# DEMO1 register map
A demo chip & its peripherals
CPU: CM4, FPU
Registers are 32-bit, access not given, no defined reset value unless marked. A register's access mark holds for its fields unless they carry their own. Offsets are from the block's base; lines under a group give offsets from that group; [hi:lo] are bit positions; {n}, {i} and the like mark numbered series; 'fields as' and 'values as' point back to an identical list; <NAME> marks a mode.

## Memory map
0x40000000 TIMER — A 16-bit timer
0x40004000 UART0 — Serial port
0x40020000 GPIOA — General-purpose I/O
0x40020400 GPIOB

## Interrupts
5 UART0
28 TIMER — Timer update

## GPIOA — General-purpose I/O
Base 0x40020000
Same registers: GPIOB 0x40020400
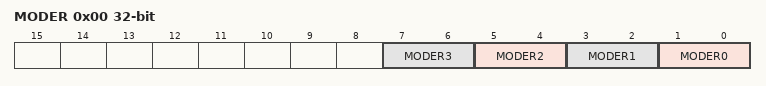
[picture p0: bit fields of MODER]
0x00 MODER — Mode register, spread over lines
  [2n+1:2n] MODER{n} (n=0..3) — Pin mode
0x14 ODR — Output data
  [1] OD1
  [0] OD0
  [0] OUT_ALIAS — Same bit as OD0
0x1C LCKR — Lock register, without fields

## TIMER — A 16-bit timer
Base 0x40000000
0x24 CNT 16-bit — Counter
  [15:0] type — a keyword as a name
{0x34+4i} CCR[{i}] (i=0..1) — Capture/compare
  [15:0] CCR
0x40 CH{x} (x=A,B; step 0x10) group
  0x00 CTRL — Channel control
    [31] EN

## UART0 — Serial port
Base 0x40004000
0x00 DATA 8-bit — Data <8 bits>
